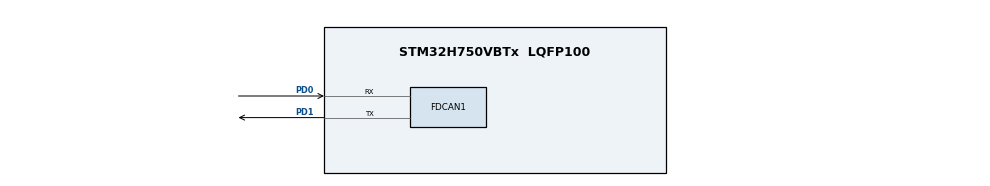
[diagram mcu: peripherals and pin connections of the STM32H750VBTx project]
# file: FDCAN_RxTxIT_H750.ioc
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FDCAN1.AutoRetransmission=ENABLE
FDCAN1.CalculateBaudRateNominal=500000
FDCAN1.CalculateTimeBitNominal=2000
FDCAN1.CalculateTimeQuantumNominal=25.0
FDCAN1.DataTimeSeg1=14
FDCAN1.DataTimeSeg2=5
FDCAN1.ExtFiltersNbr=16
FDCAN1.FrameFormat=FDCAN_FRAME_FD_BRS
FDCAN1.NominalPrescaler=1
FDCAN1.NominalSyncJumpWidth=10
FDCAN1.NominalTimeSeg1=59
FDCAN1.NominalTimeSeg2=20
FDCAN1.RxFifo0ElmtSize=FDCAN_DATA_BYTES_64
FDCAN1.RxFifo0ElmtsNbr=32
FDCAN1.StdFiltersNbr=16
FDCAN1.TxElmtSize=FDCAN_DATA_BYTES_64
FDCAN1.TxFifoQueueElmtsNbr=16
Mcu.Family=STM32H7
Mcu.Name=STM32H750VBTx
Mcu.Package=LQFP100
NVIC.FDCAN1_IT0_IRQn=true\:0\:0\:false\:false\:true\:true\:true\:true
NVIC.PriorityGroup=NVIC_PRIORITYGROUP_4
PA13\ (JTMS/SWDIO).Mode=Serial_Wire
PA13\ (JTMS/SWDIO).Signal=DEBUG_JTMS-SWDIO
PA14\ (JTCK/SWCLK).Mode=Serial_Wire
PA14\ (JTCK/SWCLK).Signal=DEBUG_JTCK-SWCLK
PD0.Mode=FDCAN_Activate
PD0.Signal=FDCAN1_RX
PD1.Mode=FDCAN_Activate
PD1.Signal=FDCAN1_TX
PH0-OSC_IN\ (PH0).Mode=HSE-External-Oscillator
PH0-OSC_IN\ (PH0).Signal=RCC_OSC_IN
PH1-OSC_OUT\ (PH1).Mode=HSE-External-Oscillator
PH1-OSC_OUT\ (PH1).Signal=RCC_OSC_OUT
ProjectManager.HeapSize=0x200
ProjectManager.StackSize=0x400
ProjectManager.TargetToolchain=STM32CubeIDE
RCC.ADCFreq_Value=80625000
RCC.APB1Freq_Value=120000000
RCC.APB2Freq_Value=120000000
RCC.APB3Freq_Value=120000000
RCC.APB4Freq_Value=120000000
RCC.CortexFreq_Value=480000000
RCC.D1PPRE=RCC_APB3_DIV2
RCC.D2PPRE1=RCC_APB1_DIV2
RCC.D2PPRE2=RCC_APB2_DIV2
RCC.D3PPRE=RCC_APB4_DIV2
RCC.DIVM1=3
RCC.DIVN1=72
RCC.FDCANCLockSelection=RCC_FDCANCLKSOURCE_HSE
RCC.HCLKFreq_Value=240000000
RCC.HPRE=RCC_HCLK_DIV2
RCC.HSE_VALUE=40000000
RCC.PLLFRACN=0
RCC.PLLSourceVirtual=RCC_PLLSOURCE_HSE
RCC.PWR_Regulator_Voltage_Scale=PWR_REGULATOR_VOLTAGE_SCALE0
RCC.ProductRev=revV
RCC.SYSCLKFreq_VALUE=480000000
RCC.SYSCLKSource=RCC_SYSCLKSOURCE_PLLCLK
RCC.USBFreq_Value=480000000
board=custom

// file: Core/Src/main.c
/* USER CODE BEGIN Header */
/**
  ******************************************************************************
  * @file           : main.c
  * @brief          : Main program body
  ******************************************************************************
  * @attention
  *
  * Copyright (c) 2023 STMicroelectronics.
  * All rights reserved.
  *
  * This software is licensed under terms that can be found in the LICENSE file
  * in the root directory of this software component.
  * If no LICENSE file comes with this software, it is provided AS-IS.
  *
  ******************************************************************************
  */
/* USER CODE END Header */
#include "main.h"

FDCAN_HandleTypeDef hfdcan1;

void SystemClock_Config(void);
static void MX_GPIO_Init(void);
static void MX_FDCAN1_Init(void);

/* USER CODE BEGIN 0 */

/**************** 以下为重写中断回调函数 ****************/
// Fifo0收到消息回调
void HAL_FDCAN_RxFifo0Callback(FDCAN_HandleTypeDef *hfdcan, uint32_t RxFifo0ITs)
{
	if (hfdcan == &hfdcan1) // 判断是hfdcan1的中断
	{
		if ((RxFifo0ITs & FDCAN_IT_RX_FIFO0_NEW_MESSAGE) != RESET) // 判断是FIFO0_NEW_MESSAGE回调
		{
			FDCAN_RxHeaderTypeDef   RxHeader; // 用来保存接收到的数据帧头部信息
			uint8_t                 RxData[64]; // 用来保存接收数据端数据

			if(HAL_FDCAN_GetRxMessage(&hfdcan1, FDCAN_RX_FIFO0, &RxHeader, RxData) == HAL_OK) // 从接收队列中读取数据帧
			{
				FDCAN_TxHeaderTypeDef   TxHeader = {0}; // 用来保存发送数据帧头部信息
				uint8_t                 TxData[64]; // 用来保存发送数据帧数据

				TxHeader.Identifier = RxHeader.Identifier;
				TxHeader.IdType = RxHeader.IdType; // 标准-FDCAN_STANDARD_ID; 扩展-FDCAN_EXTENDED_ID
				TxHeader.TxFrameType = RxHeader.RxFrameType; // 数据帧-FDCAN_DATA_FRAME; 远程帧-FDCAN_REMOTE_FRAME
				TxHeader.DataLength = RxHeader.DataLength; // FDCAN_DLC_BYTES_xx
				                                           // xx = 0 1 2 3 4 5 6 7 8 12 16 20 24 32 48 64
				TxHeader.ErrorStateIndicator = RxHeader.ErrorStateIndicator; // FDCAN_ESI_ACTIVE FDCAN_ESI_PASSIVE
				TxHeader.BitRateSwitch = RxHeader.BitRateSwitch; // 波特率不可变-FDCAN_BRS_OFF; 波特率可变-FDCAN_BRS_ON
				TxHeader.FDFormat = RxHeader.FDFormat; // 经典CAN-FDCAN_CLASSIC_CAN; CANFD-FDCAN_FD_CAN
				// TxHeader.TxEventFifoControl = FDCAN_NO_TX_EVENTS;
				// TxHeader.MessageMarker = 0;

				for(int i=0; i<64; i++)
				{
					TxData[i] = RxData[i];
				}

				while(HAL_FDCAN_GetTxFifoFreeLevel(&hfdcan1) == 0); // 等待有发送邮箱可用

				HAL_FDCAN_AddMessageToTxFifoQ(&hfdcan1, &TxHeader, TxData); // 发送数据帧
			}
		}
	}
}

/* USER CODE END 0 */

int main(void)
{

  /* MCU Configuration--------------------------------------------------------*/

  /* Reset of all peripherals, Initializes the Flash interface and the Systick. */
  HAL_Init();

  /* Configure the system clock */
  SystemClock_Config();

  /* Initialize all configured peripherals */
  MX_GPIO_Init();
  MX_FDCAN1_Init();
  /* USER CODE BEGIN 2 */

  /**************** 以下为过滤器设置 ****************/
  FDCAN_FilterTypeDef sFilterConfig;

  // 下面这组设置只接受标准帧ID为0x666的消息
  sFilterConfig.IdType = FDCAN_STANDARD_ID;
  sFilterConfig.FilterIndex = 0;
  sFilterConfig.FilterType = FDCAN_FILTER_MASK;
  sFilterConfig.FilterConfig = FDCAN_FILTER_TO_RXFIFO0;
  sFilterConfig.FilterID1 = 0x666;
  sFilterConfig.FilterID2 = 0x7FF;
  sFilterConfig.RxBufferIndex = 0;
  HAL_FDCAN_ConfigFilter(&hfdcan1, &sFilterConfig);

  // 下面这组设置只接受扩展ID为0x233和0x2233的消息
  sFilterConfig.IdType = FDCAN_EXTENDED_ID;
  sFilterConfig.FilterIndex = 0;
  sFilterConfig.FilterType = FDCAN_FILTER_MASK;
  sFilterConfig.FilterConfig = FDCAN_FILTER_TO_RXFIFO0;
  sFilterConfig.FilterID1 = 0x00002233;
  sFilterConfig.FilterID2 = 0x1FFFDFFF;
  sFilterConfig.RxBufferIndex = 0;
  HAL_FDCAN_ConfigFilter(&hfdcan1, &sFilterConfig);

  // 默认情况下，如果未配置全局过滤器，则会接收所有不匹配的帧并将其重定向到RxFIFO0
  // 后面四个参数分别 拒绝未匹配的标准数据帧 拒绝未匹配的扩展数据帧 拒绝标准远程帧 拒绝扩展远程帧
  HAL_FDCAN_ConfigGlobalFilter(&hfdcan1, FDCAN_REJECT, FDCAN_REJECT, FDCAN_REJECT_REMOTE, FDCAN_REJECT_REMOTE);

  /**************** 以下为启动中断 ****************/
  HAL_FDCAN_ActivateNotification(&hfdcan1, FDCAN_IT_RX_FIFO0_NEW_MESSAGE, 0); // 使能FIFO0数据接收中断

  /**************** 以下为启动CAN外设 ****************/
  HAL_FDCAN_Start(&hfdcan1);

  /* USER CODE END 2 */

  /* Infinite loop */
  while (1)
  {

  }
}

void SystemClock_Config(void)
{
  RCC_OscInitTypeDef RCC_OscInitStruct = {0};
  RCC_ClkInitTypeDef RCC_ClkInitStruct = {0};

  /** Supply configuration update enable
  */
  HAL_PWREx_ConfigSupply(PWR_LDO_SUPPLY);

  /** Configure the main internal regulator output voltage
  */
  __HAL_PWR_VOLTAGESCALING_CONFIG(PWR_REGULATOR_VOLTAGE_SCALE1);

  while(!__HAL_PWR_GET_FLAG(PWR_FLAG_VOSRDY)) {}

  __HAL_RCC_SYSCFG_CLK_ENABLE();
  __HAL_PWR_VOLTAGESCALING_CONFIG(PWR_REGULATOR_VOLTAGE_SCALE0);

  while(!__HAL_PWR_GET_FLAG(PWR_FLAG_VOSRDY)) {}

  /** Initializes the RCC Oscillators according to the specified parameters
  * in the RCC_OscInitTypeDef structure.
  */
  RCC_OscInitStruct.OscillatorType = RCC_OSCILLATORTYPE_HSE;
  RCC_OscInitStruct.HSEState = RCC_HSE_ON;
  RCC_OscInitStruct.PLL.PLLState = RCC_PLL_ON;
  RCC_OscInitStruct.PLL.PLLSource = RCC_PLLSOURCE_HSE;
  RCC_OscInitStruct.PLL.PLLM = 3;
  RCC_OscInitStruct.PLL.PLLN = 72;
  RCC_OscInitStruct.PLL.PLLP = 2;
  RCC_OscInitStruct.PLL.PLLQ = 2;
  RCC_OscInitStruct.PLL.PLLR = 2;
  RCC_OscInitStruct.PLL.PLLRGE = RCC_PLL1VCIRANGE_3;
  RCC_OscInitStruct.PLL.PLLVCOSEL = RCC_PLL1VCOWIDE;
  RCC_OscInitStruct.PLL.PLLFRACN = 0;
  if (HAL_RCC_OscConfig(&RCC_OscInitStruct) != HAL_OK)
  {
    Error_Handler();
  }

  /** Initializes the CPU, AHB and APB buses clocks
  */
  RCC_ClkInitStruct.ClockType = RCC_CLOCKTYPE_HCLK|RCC_CLOCKTYPE_SYSCLK
                              |RCC_CLOCKTYPE_PCLK1|RCC_CLOCKTYPE_PCLK2
                              |RCC_CLOCKTYPE_D3PCLK1|RCC_CLOCKTYPE_D1PCLK1;
  RCC_ClkInitStruct.SYSCLKSource = RCC_SYSCLKSOURCE_PLLCLK;
  RCC_ClkInitStruct.SYSCLKDivider = RCC_SYSCLK_DIV1;
  RCC_ClkInitStruct.AHBCLKDivider = RCC_HCLK_DIV2;
  RCC_ClkInitStruct.APB3CLKDivider = RCC_APB3_DIV2;
  RCC_ClkInitStruct.APB1CLKDivider = RCC_APB1_DIV2;
  RCC_ClkInitStruct.APB2CLKDivider = RCC_APB2_DIV2;
  RCC_ClkInitStruct.APB4CLKDivider = RCC_APB4_DIV2;

  if (HAL_RCC_ClockConfig(&RCC_ClkInitStruct, FLASH_LATENCY_4) != HAL_OK)
  {
    Error_Handler();
  }
}

static void MX_FDCAN1_Init(void)
{

  hfdcan1.Instance = FDCAN1;
  hfdcan1.Init.FrameFormat = FDCAN_FRAME_FD_BRS;
  hfdcan1.Init.Mode = FDCAN_MODE_NORMAL;
  hfdcan1.Init.AutoRetransmission = ENABLE;
  hfdcan1.Init.TransmitPause = DISABLE;
  hfdcan1.Init.ProtocolException = DISABLE;
  hfdcan1.Init.NominalPrescaler = 1;
  hfdcan1.Init.NominalSyncJumpWidth = 10;
  hfdcan1.Init.NominalTimeSeg1 = 59;
  hfdcan1.Init.NominalTimeSeg2 = 20;
  hfdcan1.Init.DataPrescaler = 1;
  hfdcan1.Init.DataSyncJumpWidth = 1;
  hfdcan1.Init.DataTimeSeg1 = 14;
  hfdcan1.Init.DataTimeSeg2 = 5;
  hfdcan1.Init.MessageRAMOffset = 0;
  hfdcan1.Init.StdFiltersNbr = 16;
  hfdcan1.Init.ExtFiltersNbr = 16;
  hfdcan1.Init.RxFifo0ElmtsNbr = 32;
  hfdcan1.Init.RxFifo0ElmtSize = FDCAN_DATA_BYTES_64;
  hfdcan1.Init.RxFifo1ElmtsNbr = 0;
  hfdcan1.Init.RxFifo1ElmtSize = FDCAN_DATA_BYTES_8;
  hfdcan1.Init.RxBuffersNbr = 0;
  hfdcan1.Init.RxBufferSize = FDCAN_DATA_BYTES_8;
  hfdcan1.Init.TxEventsNbr = 0;
  hfdcan1.Init.TxBuffersNbr = 0;
  hfdcan1.Init.TxFifoQueueElmtsNbr = 16;
  hfdcan1.Init.TxFifoQueueMode = FDCAN_TX_FIFO_OPERATION;
  hfdcan1.Init.TxElmtSize = FDCAN_DATA_BYTES_64;
  if (HAL_FDCAN_Init(&hfdcan1) != HAL_OK)
  {
    Error_Handler();
  }

}

static void MX_GPIO_Init(void)
{

  /* GPIO Ports Clock Enable */
  __HAL_RCC_GPIOH_CLK_ENABLE();
  __HAL_RCC_GPIOA_CLK_ENABLE();
  __HAL_RCC_GPIOD_CLK_ENABLE();

}

void Error_Handler(void)
{
  __disable_irq();
  while (1)
  {
  }
}
